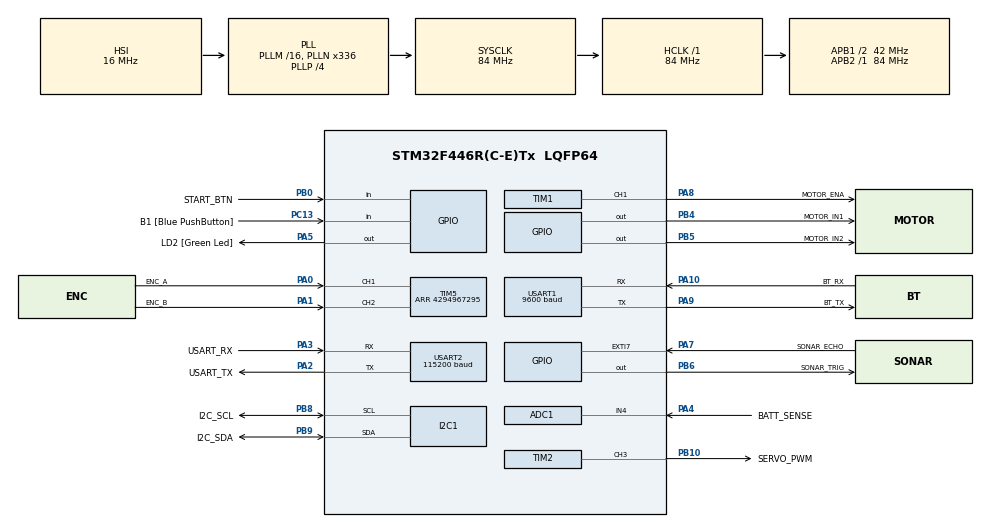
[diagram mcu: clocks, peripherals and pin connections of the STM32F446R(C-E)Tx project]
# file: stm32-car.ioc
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ADC1.Channel-0\#ChannelRegularConversion=ADC_CHANNEL_4
ADC1.NbrOfConversionFlag=1
ADC1.Rank-0\#ChannelRegularConversion=1
ADC1.SamplingTime-0\#ChannelRegularConversion=ADC_SAMPLETIME_480CYCLES
ADC1.master=1
I2C1.I2C_Mode=I2C_Fast
Mcu.Family=STM32F4
Mcu.Name=STM32F446R(C-E)Tx
Mcu.Package=LQFP64
NVIC.EXTI9_5_IRQn=true\:1\:0\:false\:false\:true\:true\:true\:true
NVIC.PriorityGroup=NVIC_PRIORITYGROUP_4
NVIC.TIM3_IRQn=true\:2\:0\:false\:false\:true\:true\:true\:true
NVIC.USART1_IRQn=true\:1\:0\:false\:false\:true\:true\:true\:true
NVIC.USART2_IRQn=true\:1\:0\:false\:false\:true\:true\:true\:true
PA0-WKUP.GPIO_Label=ENC_A
PA0-WKUP.GPIO_PuPd=GPIO_PULLUP
PA0-WKUP.Signal=S_TIM5_CH1
PA1.GPIO_Label=ENC_B
PA1.GPIO_PuPd=GPIO_PULLUP
PA1.Signal=S_TIM5_CH2
PA10.GPIO_Label=BT_RX
PA10.GPIO_PuPd=GPIO_PULLUP
PA10.Mode=Asynchronous
PA10.Signal=USART1_RX
PA13.GPIO_Label=TMS
PA13.Mode=Serial_Wire
PA13.Signal=SYS_JTMS-SWDIO
PA14.GPIO_Label=TCK
PA14.Mode=Serial_Wire
PA14.Signal=SYS_JTCK-SWCLK
PA2.GPIO_Label=USART_TX
PA2.Mode=Asynchronous
PA2.Signal=USART2_TX
PA3.GPIO_Label=USART_RX
PA3.Mode=Asynchronous
PA3.Signal=USART2_RX
PA4.GPIO_Label=BATT_SENSE
PA4.Signal=ADCx_IN4
PA5.GPIO_Label=LD2 [Green Led]
PA5.Signal=GPIO_Output
PA7.GPIO_Label=SONAR_ECHO
PA7.GPIO_ModeDefaultEXTI=GPIO_MODE_IT_RISING_FALLING
PA7.Signal=GPXTI7
PA8.GPIO_Label=MOTOR_ENA
PA8.Signal=S_TIM1_CH1
PA9.GPIO_Label=BT_TX
PA9.Mode=Asynchronous
PA9.Signal=USART1_TX
PB0.GPIO_Label=START_BTN
PB0.GPIO_PuPd=GPIO_PULLUP
PB0.Signal=GPIO_Input
PB10.GPIO_Label=SERVO_PWM
PB10.Signal=S_TIM2_CH3
PB3.GPIO_Label=SWO
PB3.Signal=SYS_JTDO-SWO
PB4.GPIO_Label=MOTOR_IN1
PB4.Signal=GPIO_Output
PB5.GPIO_Label=MOTOR_IN2
PB5.Signal=GPIO_Output
PB6.GPIO_Label=SONAR_TRIG
PB6.Signal=GPIO_Output
PB8.GPIO_Label=I2C_SCL
PB8.Mode=I2C
PB8.Signal=I2C1_SCL
PB9.GPIO_Label=I2C_SDA
PB9.Mode=I2C
PB9.Signal=I2C1_SDA
PC13.GPIO_Label=B1 [Blue PushButton]
PC13.Signal=GPIO_Input
PC14-OSC32_IN.Mode=LSE-External-Oscillator
PC14-OSC32_IN.Signal=RCC_OSC32_IN
PC15-OSC32_OUT.Mode=LSE-External-Oscillator
PC15-OSC32_OUT.Signal=RCC_OSC32_OUT
PH0-OSC_IN.Mode=HSE-External-Oscillator
PH0-OSC_IN.Signal=RCC_OSC_IN
PH1-OSC_OUT.Mode=HSE-External-Oscillator
PH1-OSC_OUT.Signal=RCC_OSC_OUT
ProjectManager.HeapSize=0x200
ProjectManager.StackSize=0x800
ProjectManager.TargetToolchain=STM32CubeIDE
RCC.48MHZClocksFreq_Value=84000000
RCC.AHBFreq_Value=84000000
RCC.APB1CLKDivider=RCC_HCLK_DIV2
RCC.APB1Freq_Value=42000000
RCC.APB1TimFreq_Value=84000000
RCC.APB2Freq_Value=84000000
RCC.APB2TimFreq_Value=84000000
RCC.CortexFreq_Value=84000000
RCC.FLatency-AdvancedSettings=FLASH_LATENCY_2
RCC.HCLKFreq_Value=84000000
RCC.HSE_VALUE=8000000
RCC.HSI_VALUE=16000000
RCC.PLLN=336
RCC.PLLP=RCC_PLLP_DIV4
RCC.SYSCLKFreq_VALUE=84000000
RCC.SYSCLKSource=RCC_SYSCLKSOURCE_PLLCLK
RCC.USBFreq_Value=168000000
RCC.VCOOutputFreq_Value=336000000
SH.ADCx_IN4.0=ADC1_IN4,IN4
SH.S_TIM1_CH1.0=TIM1_CH1,PWM Generation1 CH1
SH.S_TIM2_CH3.0=TIM2_CH3,PWM Generation3 CH3
SH.S_TIM5_CH1.0=TIM5_CH1,Encoder_Interface
SH.S_TIM5_CH2.0=TIM5_CH2,Encoder_Interface
TIM1.Channel-PWM\ Generation1\ CH1=TIM_CHANNEL_1
TIM1.Period=16799
TIM1.Prescaler=0
TIM1.Pulse-PWM\ Generation1\ CH1=0
TIM2.Channel-PWM\ Generation3\ CH3=TIM_CHANNEL_3
TIM2.Period=19999
TIM2.Prescaler=83
TIM2.Pulse-PWM\ Generation3\ CH3=1100
TIM3.Period=9999
TIM3.Prescaler=839
TIM5.EncoderMode=TIM_ENCODERMODE_TI12
TIM5.IC1Filter=6
TIM5.IC2Filter=6
TIM5.Period=4294967295
USART1.BaudRate=9600
USART1.VirtualMode=VM_ASYNC
USART2.BaudRate=115200
USART2.VirtualMode=VM_ASYNC
VP_TIM1_VS_ClockSourceINT.Mode=Internal
VP_TIM2_VS_ClockSourceINT.Mode=Internal
VP_TIM3_VS_ClockSourceINT.Mode=Internal
board=NUCLEO-F446RE

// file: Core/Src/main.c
/* USER CODE BEGIN Header */
/**
  ******************************************************************************
  * @file           : main.c
  * @brief          : MR2006B Team 7 (Ninjago) car (NUCLEO-F446RE)
  *
  * Motor (TIM1 PWM + IN1/IN2), encoder (TIM5), steering servo (TIM2),
  * battery (ADC1), OLED (I2C1), USB + Bluetooth commands, start buttons.
  * Distance runs with speed profile + PID: car_drive.c.
  * Peripheral setup (MX_..._Init) is generated by CubeMX from stm32-car.ioc.
  * App_Init() once, App_Loop() forever (car_app.c).
  ******************************************************************************
  */
/* USER CODE END Header */
#include "main.h"

/* USER CODE BEGIN Includes */
#include "car_app.h"
#include "car_drive.h"
#include "car_hw.h"
/* USER CODE END Includes */

ADC_HandleTypeDef hadc1;

I2C_HandleTypeDef hi2c1;

TIM_HandleTypeDef htim1;
TIM_HandleTypeDef htim2;
TIM_HandleTypeDef htim3;
TIM_HandleTypeDef htim5;

UART_HandleTypeDef huart1;
UART_HandleTypeDef huart2;

void SystemClock_Config(void);
static void MX_GPIO_Init(void);
static void MX_USART2_UART_Init(void);
static void MX_TIM1_Init(void);
static void MX_TIM5_Init(void);
static void MX_USART1_UART_Init(void);
static void MX_I2C1_Init(void);
static void MX_TIM2_Init(void);
static void MX_ADC1_Init(void);
static void MX_TIM3_Init(void);

int main(void)
{

  /* MCU Configuration--------------------------------------------------------*/

  /* Reset of all peripherals, Initializes the Flash interface and the Systick. */
  HAL_Init();

  /* Configure the system clock */
  SystemClock_Config();

  /* Initialize all configured peripherals */
  MX_GPIO_Init();
  MX_USART2_UART_Init();
  MX_TIM1_Init();
  MX_TIM5_Init();
  MX_USART1_UART_Init();
  MX_I2C1_Init();
  MX_TIM2_Init();
  MX_ADC1_Init();
  MX_TIM3_Init();
  /* USER CODE BEGIN 2 */
  App_Init();
  HAL_TIM_Base_Start_IT(&htim3);   /* control loop interrupt every 100 ms */
  /* USER CODE END 2 */

  /* Infinite loop */
  while (1)
  {

    /* USER CODE BEGIN 3 */
    App_Loop();
  }
  /* USER CODE END 3 */
}

void SystemClock_Config(void)
{
  RCC_OscInitTypeDef RCC_OscInitStruct = {0};
  RCC_ClkInitTypeDef RCC_ClkInitStruct = {0};

  /** Configure the main internal regulator output voltage
  */
  __HAL_RCC_PWR_CLK_ENABLE();
  __HAL_PWR_VOLTAGESCALING_CONFIG(PWR_REGULATOR_VOLTAGE_SCALE3);

  /** Initializes the RCC Oscillators according to the specified parameters
  * in the RCC_OscInitTypeDef structure.
  */
  RCC_OscInitStruct.OscillatorType = RCC_OSCILLATORTYPE_HSI;
  RCC_OscInitStruct.HSIState = RCC_HSI_ON;
  RCC_OscInitStruct.HSICalibrationValue = RCC_HSICALIBRATION_DEFAULT;
  RCC_OscInitStruct.PLL.PLLState = RCC_PLL_ON;
  RCC_OscInitStruct.PLL.PLLSource = RCC_PLLSOURCE_HSI;
  RCC_OscInitStruct.PLL.PLLM = 16;
  RCC_OscInitStruct.PLL.PLLN = 336;
  RCC_OscInitStruct.PLL.PLLP = RCC_PLLP_DIV4;
  RCC_OscInitStruct.PLL.PLLQ = 2;
  RCC_OscInitStruct.PLL.PLLR = 2;
  if (HAL_RCC_OscConfig(&RCC_OscInitStruct) != HAL_OK)
  {
    Error_Handler();
  }

  /** Initializes the CPU, AHB and APB buses clocks
  */
  RCC_ClkInitStruct.ClockType = RCC_CLOCKTYPE_HCLK|RCC_CLOCKTYPE_SYSCLK
                              |RCC_CLOCKTYPE_PCLK1|RCC_CLOCKTYPE_PCLK2;
  RCC_ClkInitStruct.SYSCLKSource = RCC_SYSCLKSOURCE_PLLCLK;
  RCC_ClkInitStruct.AHBCLKDivider = RCC_SYSCLK_DIV1;
  RCC_ClkInitStruct.APB1CLKDivider = RCC_HCLK_DIV2;
  RCC_ClkInitStruct.APB2CLKDivider = RCC_HCLK_DIV1;

  if (HAL_RCC_ClockConfig(&RCC_ClkInitStruct, FLASH_LATENCY_2) != HAL_OK)
  {
    Error_Handler();
  }
}

static void MX_ADC1_Init(void)
{

  ADC_ChannelConfTypeDef sConfig = {0};

  /** Configure the global features of the ADC (Clock, Resolution, Data Alignment and number of conversion)
  */
  hadc1.Instance = ADC1;
  hadc1.Init.ClockPrescaler = ADC_CLOCK_SYNC_PCLK_DIV4;
  hadc1.Init.Resolution = ADC_RESOLUTION_12B;
  hadc1.Init.ScanConvMode = DISABLE;
  hadc1.Init.ContinuousConvMode = DISABLE;
  hadc1.Init.DiscontinuousConvMode = DISABLE;
  hadc1.Init.ExternalTrigConvEdge = ADC_EXTERNALTRIGCONVEDGE_NONE;
  hadc1.Init.ExternalTrigConv = ADC_SOFTWARE_START;
  hadc1.Init.DataAlign = ADC_DATAALIGN_RIGHT;
  hadc1.Init.NbrOfConversion = 1;
  hadc1.Init.DMAContinuousRequests = DISABLE;
  hadc1.Init.EOCSelection = ADC_EOC_SINGLE_CONV;
  if (HAL_ADC_Init(&hadc1) != HAL_OK)
  {
    Error_Handler();
  }

  /** Configure for the selected ADC regular channel its corresponding rank in the sequencer and its sample time.
  */
  sConfig.Channel = ADC_CHANNEL_4;
  sConfig.Rank = 1;
  sConfig.SamplingTime = ADC_SAMPLETIME_480CYCLES;
  if (HAL_ADC_ConfigChannel(&hadc1, &sConfig) != HAL_OK)
  {
    Error_Handler();
  }

}

static void MX_I2C1_Init(void)
{

  hi2c1.Instance = I2C1;
  hi2c1.Init.ClockSpeed = 400000;
  hi2c1.Init.DutyCycle = I2C_DUTYCYCLE_2;
  hi2c1.Init.OwnAddress1 = 0;
  hi2c1.Init.AddressingMode = I2C_ADDRESSINGMODE_7BIT;
  hi2c1.Init.DualAddressMode = I2C_DUALADDRESS_DISABLE;
  hi2c1.Init.OwnAddress2 = 0;
  hi2c1.Init.GeneralCallMode = I2C_GENERALCALL_DISABLE;
  hi2c1.Init.NoStretchMode = I2C_NOSTRETCH_DISABLE;
  if (HAL_I2C_Init(&hi2c1) != HAL_OK)
  {
    Error_Handler();
  }

}

static void MX_TIM1_Init(void)
{

  TIM_ClockConfigTypeDef sClockSourceConfig = {0};
  TIM_MasterConfigTypeDef sMasterConfig = {0};
  TIM_OC_InitTypeDef sConfigOC = {0};
  TIM_BreakDeadTimeConfigTypeDef sBreakDeadTimeConfig = {0};

  htim1.Instance = TIM1;
  htim1.Init.Prescaler = 0;
  htim1.Init.CounterMode = TIM_COUNTERMODE_UP;
  htim1.Init.Period = 16799;
  htim1.Init.ClockDivision = TIM_CLOCKDIVISION_DIV1;
  htim1.Init.RepetitionCounter = 0;
  htim1.Init.AutoReloadPreload = TIM_AUTORELOAD_PRELOAD_DISABLE;
  if (HAL_TIM_Base_Init(&htim1) != HAL_OK)
  {
    Error_Handler();
  }
  sClockSourceConfig.ClockSource = TIM_CLOCKSOURCE_INTERNAL;
  if (HAL_TIM_ConfigClockSource(&htim1, &sClockSourceConfig) != HAL_OK)
  {
    Error_Handler();
  }
  if (HAL_TIM_PWM_Init(&htim1) != HAL_OK)
  {
    Error_Handler();
  }
  sMasterConfig.MasterOutputTrigger = TIM_TRGO_RESET;
  sMasterConfig.MasterSlaveMode = TIM_MASTERSLAVEMODE_DISABLE;
  if (HAL_TIMEx_MasterConfigSynchronization(&htim1, &sMasterConfig) != HAL_OK)
  {
    Error_Handler();
  }
  sConfigOC.OCMode = TIM_OCMODE_PWM1;
  sConfigOC.Pulse = 0;
  sConfigOC.OCPolarity = TIM_OCPOLARITY_HIGH;
  sConfigOC.OCNPolarity = TIM_OCNPOLARITY_HIGH;
  sConfigOC.OCFastMode = TIM_OCFAST_DISABLE;
  sConfigOC.OCIdleState = TIM_OCIDLESTATE_RESET;
  sConfigOC.OCNIdleState = TIM_OCNIDLESTATE_RESET;
  if (HAL_TIM_PWM_ConfigChannel(&htim1, &sConfigOC, TIM_CHANNEL_1) != HAL_OK)
  {
    Error_Handler();
  }
  sBreakDeadTimeConfig.OffStateRunMode = TIM_OSSR_DISABLE;
  sBreakDeadTimeConfig.OffStateIDLEMode = TIM_OSSI_DISABLE;
  sBreakDeadTimeConfig.LockLevel = TIM_LOCKLEVEL_OFF;
  sBreakDeadTimeConfig.DeadTime = 0;
  sBreakDeadTimeConfig.BreakState = TIM_BREAK_DISABLE;
  sBreakDeadTimeConfig.BreakPolarity = TIM_BREAKPOLARITY_HIGH;
  sBreakDeadTimeConfig.AutomaticOutput = TIM_AUTOMATICOUTPUT_DISABLE;
  if (HAL_TIMEx_ConfigBreakDeadTime(&htim1, &sBreakDeadTimeConfig) != HAL_OK)
  {
    Error_Handler();
  }
  HAL_TIM_MspPostInit(&htim1);

}

static void MX_TIM2_Init(void)
{

  TIM_ClockConfigTypeDef sClockSourceConfig = {0};
  TIM_MasterConfigTypeDef sMasterConfig = {0};
  TIM_OC_InitTypeDef sConfigOC = {0};

  htim2.Instance = TIM2;
  htim2.Init.Prescaler = 83;
  htim2.Init.CounterMode = TIM_COUNTERMODE_UP;
  htim2.Init.Period = 19999;
  htim2.Init.ClockDivision = TIM_CLOCKDIVISION_DIV1;
  htim2.Init.AutoReloadPreload = TIM_AUTORELOAD_PRELOAD_DISABLE;
  if (HAL_TIM_Base_Init(&htim2) != HAL_OK)
  {
    Error_Handler();
  }
  sClockSourceConfig.ClockSource = TIM_CLOCKSOURCE_INTERNAL;
  if (HAL_TIM_ConfigClockSource(&htim2, &sClockSourceConfig) != HAL_OK)
  {
    Error_Handler();
  }
  if (HAL_TIM_PWM_Init(&htim2) != HAL_OK)
  {
    Error_Handler();
  }
  sMasterConfig.MasterOutputTrigger = TIM_TRGO_RESET;
  sMasterConfig.MasterSlaveMode = TIM_MASTERSLAVEMODE_DISABLE;
  if (HAL_TIMEx_MasterConfigSynchronization(&htim2, &sMasterConfig) != HAL_OK)
  {
    Error_Handler();
  }
  sConfigOC.OCMode = TIM_OCMODE_PWM1;
  sConfigOC.Pulse = 1100;
  sConfigOC.OCPolarity = TIM_OCPOLARITY_HIGH;
  sConfigOC.OCFastMode = TIM_OCFAST_DISABLE;
  if (HAL_TIM_PWM_ConfigChannel(&htim2, &sConfigOC, TIM_CHANNEL_3) != HAL_OK)
  {
    Error_Handler();
  }
  HAL_TIM_MspPostInit(&htim2);

}

static void MX_TIM3_Init(void)
{

  TIM_ClockConfigTypeDef sClockSourceConfig = {0};
  TIM_MasterConfigTypeDef sMasterConfig = {0};

  htim3.Instance = TIM3;
  htim3.Init.Prescaler = 839;
  htim3.Init.CounterMode = TIM_COUNTERMODE_UP;
  htim3.Init.Period = 9999;
  htim3.Init.ClockDivision = TIM_CLOCKDIVISION_DIV1;
  htim3.Init.AutoReloadPreload = TIM_AUTORELOAD_PRELOAD_DISABLE;
  if (HAL_TIM_Base_Init(&htim3) != HAL_OK)
  {
    Error_Handler();
  }
  sClockSourceConfig.ClockSource = TIM_CLOCKSOURCE_INTERNAL;
  if (HAL_TIM_ConfigClockSource(&htim3, &sClockSourceConfig) != HAL_OK)
  {
    Error_Handler();
  }
  sMasterConfig.MasterOutputTrigger = TIM_TRGO_RESET;
  sMasterConfig.MasterSlaveMode = TIM_MASTERSLAVEMODE_DISABLE;
  if (HAL_TIMEx_MasterConfigSynchronization(&htim3, &sMasterConfig) != HAL_OK)
  {
    Error_Handler();
  }

}

static void MX_TIM5_Init(void)
{

  TIM_Encoder_InitTypeDef sConfig = {0};
  TIM_MasterConfigTypeDef sMasterConfig = {0};

  htim5.Instance = TIM5;
  htim5.Init.Prescaler = 0;
  htim5.Init.CounterMode = TIM_COUNTERMODE_UP;
  htim5.Init.Period = 4294967295;
  htim5.Init.ClockDivision = TIM_CLOCKDIVISION_DIV1;
  htim5.Init.AutoReloadPreload = TIM_AUTORELOAD_PRELOAD_DISABLE;
  sConfig.EncoderMode = TIM_ENCODERMODE_TI12;
  sConfig.IC1Polarity = TIM_ICPOLARITY_RISING;
  sConfig.IC1Selection = TIM_ICSELECTION_DIRECTTI;
  sConfig.IC1Prescaler = TIM_ICPSC_DIV1;
  sConfig.IC1Filter = 6;
  sConfig.IC2Polarity = TIM_ICPOLARITY_RISING;
  sConfig.IC2Selection = TIM_ICSELECTION_DIRECTTI;
  sConfig.IC2Prescaler = TIM_ICPSC_DIV1;
  sConfig.IC2Filter = 6;
  if (HAL_TIM_Encoder_Init(&htim5, &sConfig) != HAL_OK)
  {
    Error_Handler();
  }
  sMasterConfig.MasterOutputTrigger = TIM_TRGO_RESET;
  sMasterConfig.MasterSlaveMode = TIM_MASTERSLAVEMODE_DISABLE;
  if (HAL_TIMEx_MasterConfigSynchronization(&htim5, &sMasterConfig) != HAL_OK)
  {
    Error_Handler();
  }

}

static void MX_USART1_UART_Init(void)
{

  huart1.Instance = USART1;
  huart1.Init.BaudRate = 9600;
  huart1.Init.WordLength = UART_WORDLENGTH_8B;
  huart1.Init.StopBits = UART_STOPBITS_1;
  huart1.Init.Parity = UART_PARITY_NONE;
  huart1.Init.Mode = UART_MODE_TX_RX;
  huart1.Init.HwFlowCtl = UART_HWCONTROL_NONE;
  huart1.Init.OverSampling = UART_OVERSAMPLING_16;
  if (HAL_UART_Init(&huart1) != HAL_OK)
  {
    Error_Handler();
  }

}

static void MX_USART2_UART_Init(void)
{

  huart2.Instance = USART2;
  huart2.Init.BaudRate = 115200;
  huart2.Init.WordLength = UART_WORDLENGTH_8B;
  huart2.Init.StopBits = UART_STOPBITS_1;
  huart2.Init.Parity = UART_PARITY_NONE;
  huart2.Init.Mode = UART_MODE_TX_RX;
  huart2.Init.HwFlowCtl = UART_HWCONTROL_NONE;
  huart2.Init.OverSampling = UART_OVERSAMPLING_16;
  if (HAL_UART_Init(&huart2) != HAL_OK)
  {
    Error_Handler();
  }

}

static void MX_GPIO_Init(void)
{
  GPIO_InitTypeDef GPIO_InitStruct = {0};

  /* GPIO Ports Clock Enable */
  __HAL_RCC_GPIOC_CLK_ENABLE();
  __HAL_RCC_GPIOH_CLK_ENABLE();
  __HAL_RCC_GPIOA_CLK_ENABLE();
  __HAL_RCC_GPIOB_CLK_ENABLE();

  /*Configure GPIO pin Output Level */
  HAL_GPIO_WritePin(LD2_GPIO_Port, LD2_Pin, GPIO_PIN_RESET);

  /*Configure GPIO pin Output Level */
  HAL_GPIO_WritePin(GPIOB, MOTOR_IN1_Pin|MOTOR_IN2_Pin|SONAR_TRIG_Pin, GPIO_PIN_RESET);

  /*Configure GPIO pin : B1_Pin */
  GPIO_InitStruct.Pin = B1_Pin;
  GPIO_InitStruct.Mode = GPIO_MODE_INPUT;
  GPIO_InitStruct.Pull = GPIO_NOPULL;
  HAL_GPIO_Init(B1_GPIO_Port, &GPIO_InitStruct);

  /*Configure GPIO pin : LD2_Pin */
  GPIO_InitStruct.Pin = LD2_Pin;
  GPIO_InitStruct.Mode = GPIO_MODE_OUTPUT_PP;
  GPIO_InitStruct.Pull = GPIO_NOPULL;
  GPIO_InitStruct.Speed = GPIO_SPEED_FREQ_LOW;
  HAL_GPIO_Init(LD2_GPIO_Port, &GPIO_InitStruct);

  /*Configure GPIO pin : SONAR_ECHO_Pin */
  GPIO_InitStruct.Pin = SONAR_ECHO_Pin;
  GPIO_InitStruct.Mode = GPIO_MODE_IT_RISING_FALLING;
  GPIO_InitStruct.Pull = GPIO_NOPULL;
  HAL_GPIO_Init(SONAR_ECHO_GPIO_Port, &GPIO_InitStruct);

  /*Configure GPIO pin : START_BTN_Pin */
  GPIO_InitStruct.Pin = START_BTN_Pin;
  GPIO_InitStruct.Mode = GPIO_MODE_INPUT;
  GPIO_InitStruct.Pull = GPIO_PULLUP;
  HAL_GPIO_Init(START_BTN_GPIO_Port, &GPIO_InitStruct);

  /*Configure GPIO pins : MOTOR_IN1_Pin MOTOR_IN2_Pin SONAR_TRIG_Pin */
  GPIO_InitStruct.Pin = MOTOR_IN1_Pin|MOTOR_IN2_Pin|SONAR_TRIG_Pin;
  GPIO_InitStruct.Mode = GPIO_MODE_OUTPUT_PP;
  GPIO_InitStruct.Pull = GPIO_NOPULL;
  GPIO_InitStruct.Speed = GPIO_SPEED_FREQ_LOW;
  HAL_GPIO_Init(GPIOB, &GPIO_InitStruct);

  /* EXTI interrupt init*/
  HAL_NVIC_SetPriority(EXTI9_5_IRQn, 1, 0);
  HAL_NVIC_EnableIRQ(EXTI9_5_IRQn);

}

/* USER CODE BEGIN 4 */
/* TIM3 update interrupt, every 100 ms: one control step (car_drive.c).
 * F = 84 MHz / ((PSC+1) * (ARR+1)) = 84 MHz / (840 * 10000) = 10 Hz */
void HAL_TIM_PeriodElapsedCallback(TIM_HandleTypeDef *htim)
{
  if (htim->Instance == TIM3) drive_update();
}

/* PA7 (HC-SR04 ECHO), both edges: time the echo pulse (car_hw.c) */
void HAL_GPIO_EXTI_Callback(uint16_t GPIO_Pin)
{
  if (GPIO_Pin == SONAR_ECHO_Pin) sonar_echo_edge();
}
/* USER CODE END 4 */

void Error_Handler(void)
{
  __disable_irq();
  while (1)
  {
  }
}
